# CIU32L051 register map
File version: 1.0.0
Registers are 32-bit, read-write, reset 0x0 unless marked. A register's access mark holds for its fields unless they carry their own. Offsets are from the block's base; [hi:lo] are bit positions; {n}, {i} and the like mark numbered series.

## LPTIM1
Base 0x40007C00
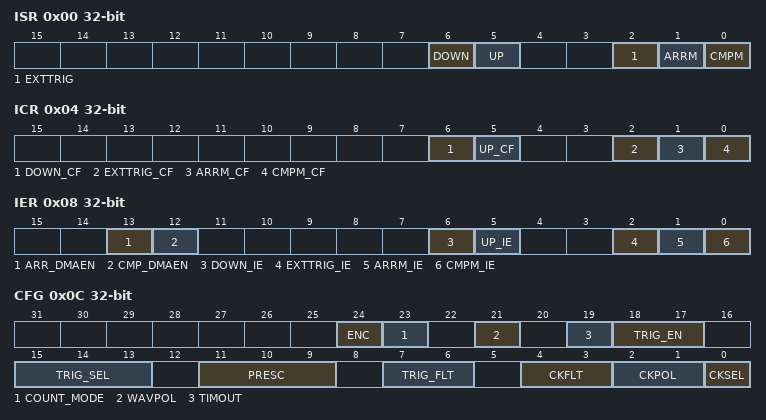
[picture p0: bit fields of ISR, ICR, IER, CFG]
0x00 ISR
  [6] DOWN, [5] UP, [2] EXTTRIG, [1] ARRM, [0] CMPM
0x04 ICR
  [6] DOWN_CF, [5] UP_CF, [2] EXTTRIG_CF, [1] ARRM_CF, [0] CMPM_CF
0x08 IER
  [13] ARR_DMAEN, [12] CMP_DMAEN, [6] DOWN_IE, [5] UP_IE, [2] EXTTRIG_IE, [1] ARRM_IE, [0] CMPM_IE
0x0C CFG
  [24] ENC, [23] COUNT_MODE, [21] WAVPOL, [19] TIMOUT, [18:17] TRIG_EN, [15:13] TRIG_SEL, [11:9] PRESC, [7:6] TRIG_FLT, [4:3] CKFLT, [2:1] CKPOL, [0] CKSEL
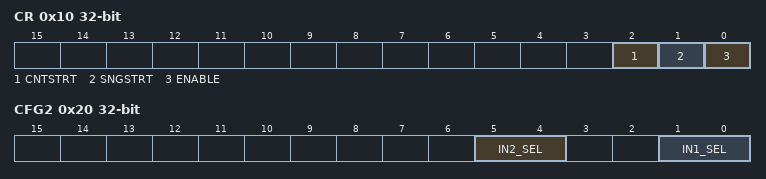
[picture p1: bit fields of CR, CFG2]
0x10 CR
  [2] CNTSTRT, [1] SNGSTRT, [0] ENABLE
0x14 CMP
  [15:0] CMP
0x18 ARR reset 0x1
  [15:0] ARR
0x1C CNT
  [15:0] CNT
0x20 CFG2
  [5:4] IN2_SEL, [1:0] IN1_SEL

## LPTIM2
Base 0x40009000
0x00 ISR
  [1] ARRM
0x04 ICR
  [1] ARRM_CF
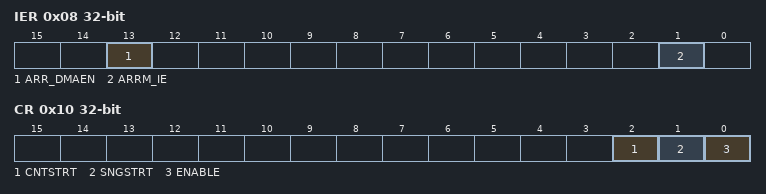
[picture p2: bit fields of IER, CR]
0x08 IER
  [13] ARR_DMAEN, [1] ARRM_IE
0x0C CFG
  [11:9] PRESC
0x10 CR
  [2] CNTSTRT, [1] SNGSTRT, [0] ENABLE
0x18 ARR reset 0x1
  [15:0] ARR
0x1C CNT
  [15:0] CNT

## LPUART1
Base 0x40008000
Same registers: LPUART2 0x40008400
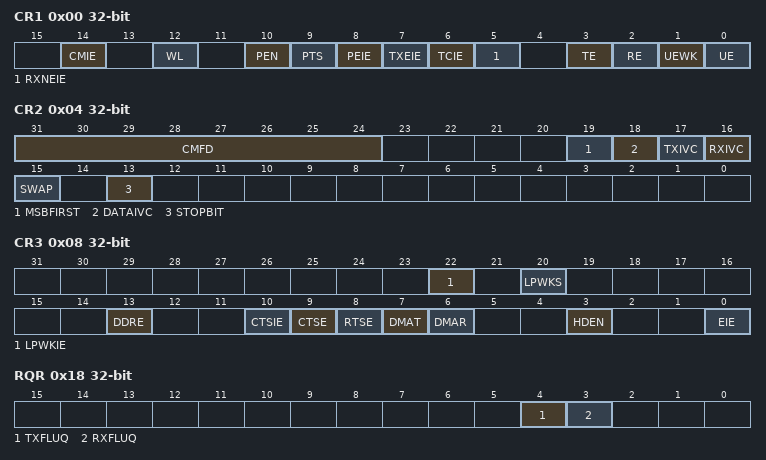
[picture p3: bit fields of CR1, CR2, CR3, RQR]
0x00 CR1
  [14] CMIE, [12] WL, [10] PEN, [9] PTS, [8] PEIE, [7] TXEIE, [6] TCIE, [5] RXNEIE, [3] TE, [2] RE, [1] UEWK, [0] UE
0x04 CR2
  [31:24] CMFD, [19] MSBFIRST, [18] DATAIVC, [17] TXIVC, [16] RXIVC, [15] SWAP, [13] STOPBIT
0x08 CR3
  [22] LPWKIE, [20] LPWKS, [13] DDRE, [10] CTSIE, [9] CTSE, [8] RTSE, [7] DMAT, [6] DMAR, [3] HDEN, [0] EIE
0x0C BRR
  [19:0] BRR
0x18 RQR
  [4] TXFLUQ, [3] RXFLUQ
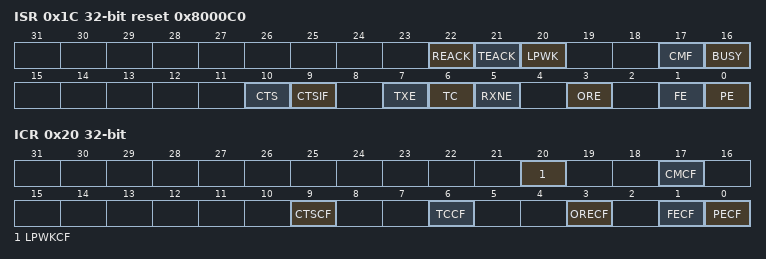
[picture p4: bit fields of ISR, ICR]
0x1C ISR reset 0x8000C0
  [22] REACK, [21] TEACK, [20] LPWK, [17] CMF, [16] BUSY, [10] CTS, [9] CTSIF, [7] TXE, [6] TC, [5] RXNE, [3] ORE, [1] FE, [0] PE
0x20 ICR
  [20] LPWKCF, [17] CMCF, [9] CTSCF, [6] TCCF, [3] ORECF, [1] FECF, [0] PECF
0x24 RDR
  [8:0] RDR
0x28 TDR
  [8:0] TDR
0x2C PRESC
  [3:0] PRESCALER

## NVIC
Base 0xE000E100
0x00 ISER
  [31:0] SETENA
0x80 ICER
  [31:0] CLRENA
0x100 ISPR
  [31:0] SETPEND
0x180 ICPR
  [31:0] CLRPEND
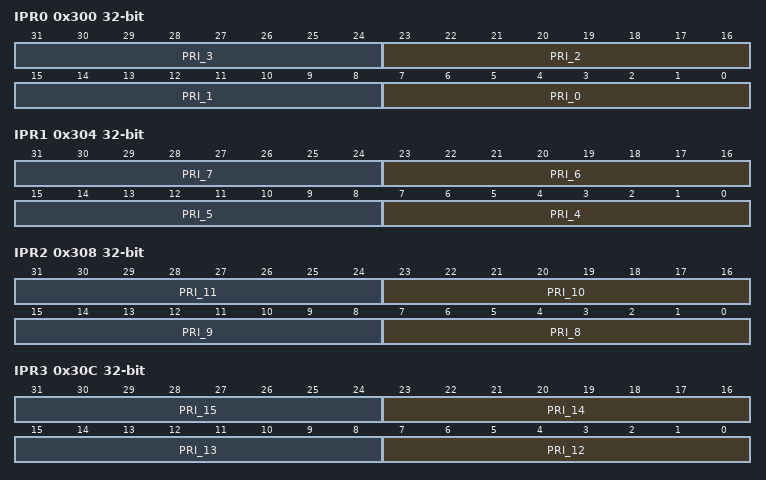
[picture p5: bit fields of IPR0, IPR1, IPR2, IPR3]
0x300 IPR0
  [8n+7:8n] PRI_{n} (n=0..3)
0x304 IPR1
  [8n-25:8n-32] PRI_{n} (n=4..7)
0x308 IPR2
  [8n-57:8n-64] PRI_{n} (n=8..11)
0x30C IPR3
  [8n-89:8n-96] PRI_{n} (n=12..15)
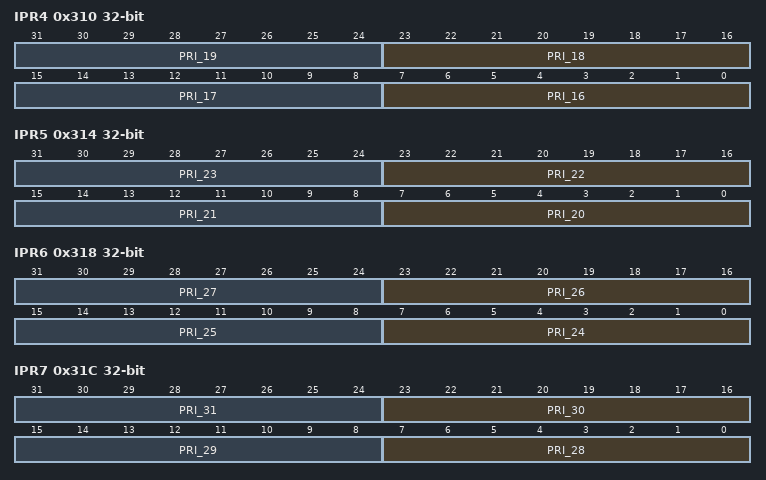
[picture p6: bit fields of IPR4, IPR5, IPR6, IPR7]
0x310 IPR4
  [8n-121:8n-128] PRI_{n} (n=16..19)
0x314 IPR5
  [8n-153:8n-160] PRI_{n} (n=20..23)
0x318 IPR6
  [8n-185:8n-192] PRI_{n} (n=24..27)
0x31C IPR7
  [8n-217:8n-224] PRI_{n} (n=28..31)

## PMU
Base 0x40007000
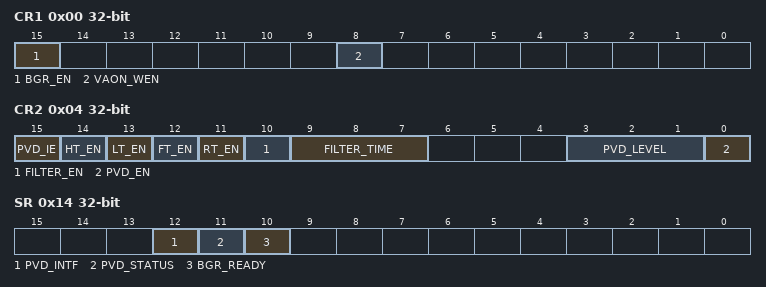
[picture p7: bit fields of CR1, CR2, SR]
0x00 CR1
  [15] BGR_EN, [8] VAON_WEN
0x04 CR2
  [15] PVD_IE, [14] HT_EN, [13] LT_EN, [12] FT_EN, [11] RT_EN, [10] FILTER_EN, [9:7] FILTER_TIME, [3:1] PVD_LEVEL, [0] PVD_EN
0x08 CR3
  [9] ULP_EN
0x14 SR
  [12] PVD_INTF, [11] PVD_STATUS, [10] BGR_READY
0x18 CLR
  [12] PVD_INTF_CLR

## RCC
Base 0x40021000
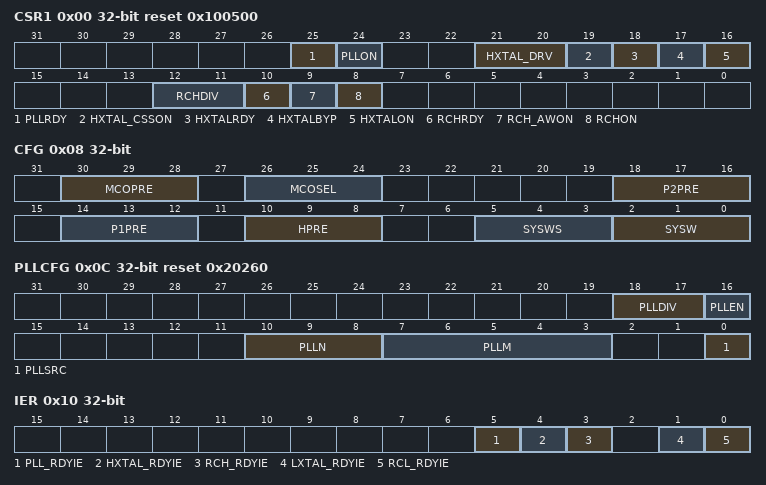
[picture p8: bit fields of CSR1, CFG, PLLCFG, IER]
0x00 CSR1 reset 0x100500
  [25] PLLRDY, [24] PLLON, [21:20] HXTAL_DRV, [19] HXTAL_CSSON, [18] HXTALRDY, [17] HXTALBYP, [16] HXTALON, [12:11] RCHDIV, [10] RCHRDY, [9] RCH_AWON, [8] RCHON
0x04 STABC reset 0x3
  [1:0] HXTAL_STAB_SEL
0x08 CFG
  [30:28] MCOPRE, [26:24] MCOSEL, [18:16] P2PRE, [14:12] P1PRE, [10:8] HPRE, [5:3] SYSWS, [2:0] SYSW
0x0C PLLCFG reset 0x20260
  [18:17] PLLDIV, [16] PLLEN, [10:8] PLLN, [7:3] PLLM, [0] PLLSRC
0x10 IER
  [5] PLL_RDYIE, [4] HXTAL_RDYIE, [3] RCH_RDYIE, [1] LXTAL_RDYIE, [0] RCL_RDYIE
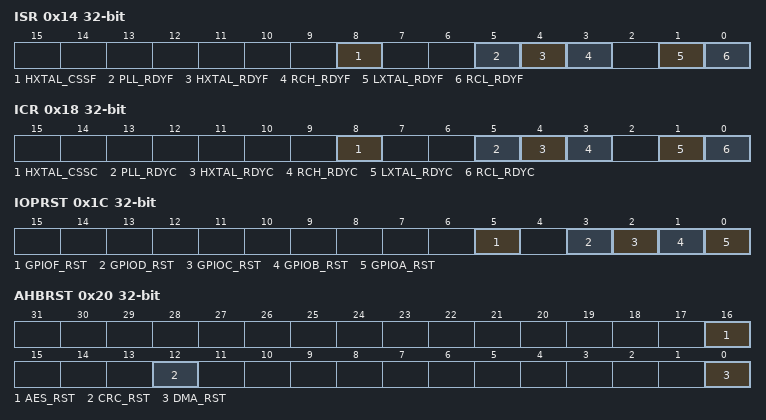
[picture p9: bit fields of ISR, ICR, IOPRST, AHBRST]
0x14 ISR
  [8] HXTAL_CSSF, [5] PLL_RDYF, [4] HXTAL_RDYF, [3] RCH_RDYF, [1] LXTAL_RDYF, [0] RCL_RDYF
0x18 ICR
  [8] HXTAL_CSSC, [5] PLL_RDYC, [4] HXTAL_RDYC, [3] RCH_RDYC, [1] LXTAL_RDYC, [0] RCL_RDYC
0x1C IOPRST
  [5] GPIOF_RST, [3] GPIOD_RST, [2] GPIOC_RST, [1] GPIOB_RST, [0] GPIOA_RST
0x20 AHBRST
  [16] AES_RST, [12] CRC_RST, [0] DMA_RST
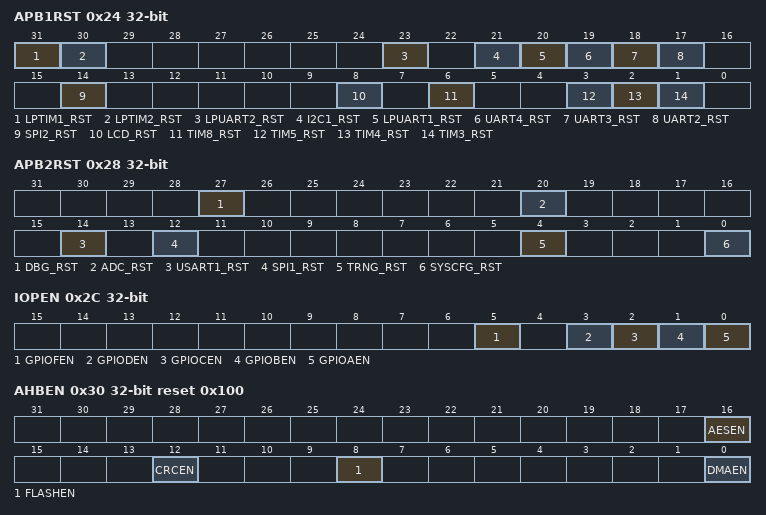
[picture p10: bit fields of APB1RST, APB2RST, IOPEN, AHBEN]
0x24 APB1RST
  [31] LPTIM1_RST, [30] LPTIM2_RST, [23] LPUART2_RST, [21] I2C1_RST, [20] LPUART1_RST, [19] UART4_RST, [18] UART3_RST, [17] UART2_RST, [14] SPI2_RST, [8] LCD_RST, [6] TIM8_RST, [3] TIM5_RST, [2] TIM4_RST, [1] TIM3_RST
0x28 APB2RST
  [27] DBG_RST, [20] ADC_RST, [14] USART1_RST, [12] SPI1_RST, [4] TRNG_RST, [0] SYSCFG_RST
0x2C IOPEN
  [5] GPIOFEN, [3] GPIODEN, [2] GPIOCEN, [1] GPIOBEN, [0] GPIOAEN
0x30 AHBEN reset 0x100
  [16] AESEN, [12] CRCEN, [8] FLASHEN, [0] DMAEN
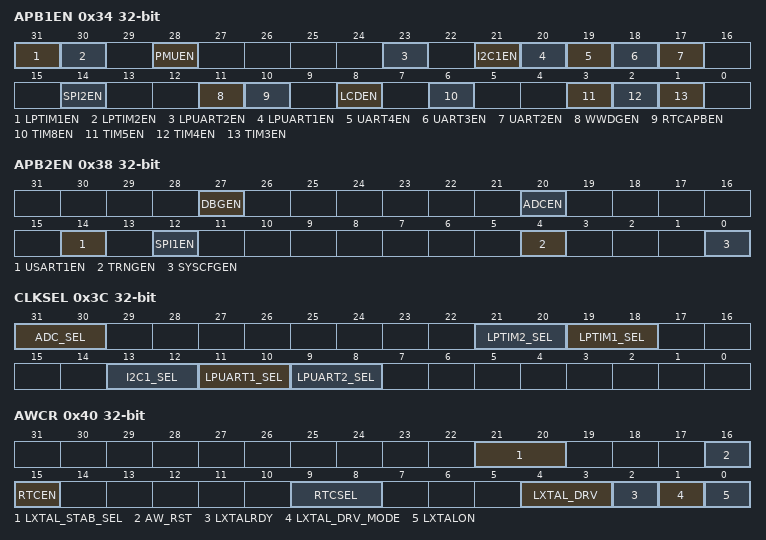
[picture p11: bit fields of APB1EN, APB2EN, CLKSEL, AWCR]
0x34 APB1EN
  [31] LPTIM1EN, [30] LPTIM2EN, [28] PMUEN, [23] LPUART2EN, [21] I2C1EN, [20] LPUART1EN, [19] UART4EN, [18] UART3EN, [17] UART2EN, [14] SPI2EN, [11] WWDGEN, [10] RTCAPBEN, [8] LCDEN, [6] TIM8EN, [3] TIM5EN, [2] TIM4EN, [1] TIM3EN
0x38 APB2EN
  [27] DBGEN, [20] ADCEN, [14] USART1EN, [12] SPI1EN, [4] TRNGEN, [0] SYSCFGEN
0x3C CLKSEL
  [31:30] ADC_SEL, [21:20] LPTIM2_SEL, [19:18] LPTIM1_SEL, [13:12] I2C1_SEL, [11:10] LPUART1_SEL, [9:8] LPUART2_SEL
0x40 AWCR
  [21:20] LXTAL_STAB_SEL, [16] AW_RST, [15] RTCEN, [9:8] RTCSEL, [4:3] LXTAL_DRV, [2] LXTALRDY, [1] LXTAL_DRV_MODE, [0] LXTALON
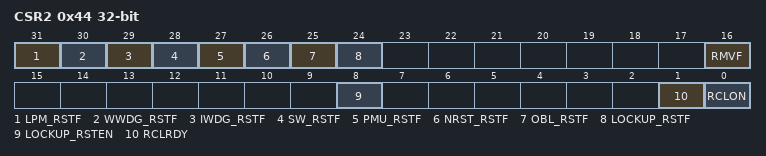
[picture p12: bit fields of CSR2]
0x44 CSR2
  [31] LPM_RSTF, [30] WWDG_RSTF, [29] IWDG_RSTF, [28] SW_RSTF, [27] PMU_RSTF, [26] NRST_RSTF, [25] OBL_RSTF, [24] LOCKUP_RSTF, [16] RMVF, [8] LOCKUP_RSTEN, [1] RCLRDY, [0] RCLON
0x50 RCLCAL
  [4:0] RCL_CAL
0x54 RCHCAL
  [6:0] RCH_CAL
0x100 VREFBUFCAL
  [6:0] VREFBUF_CAL
